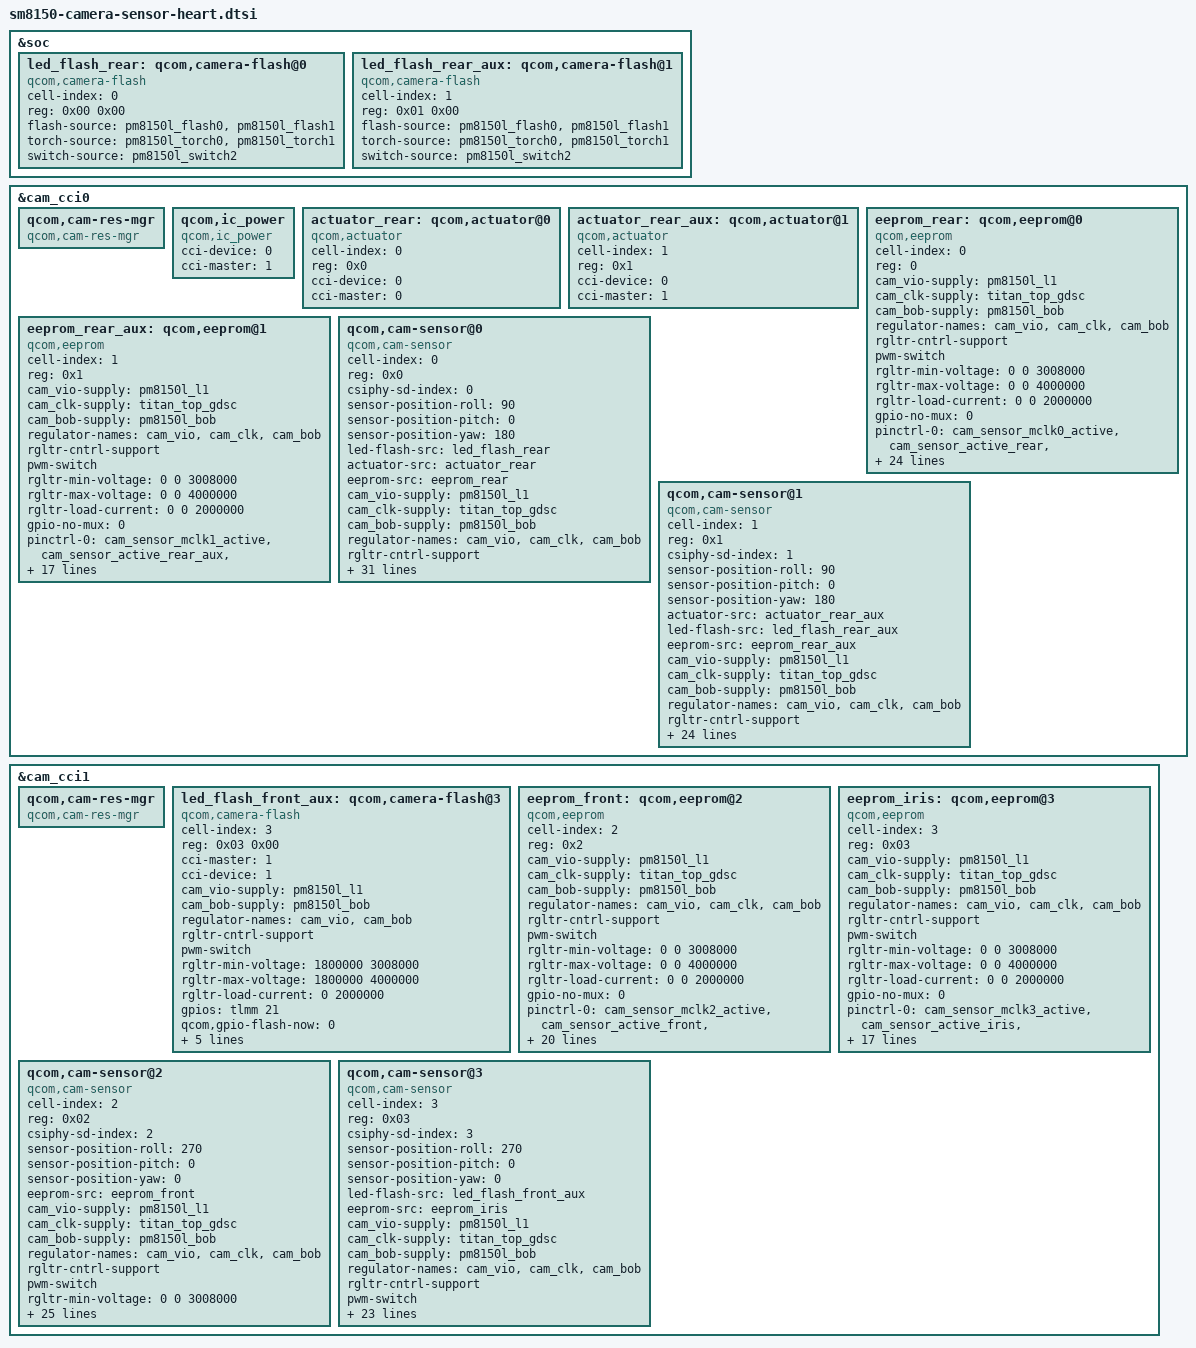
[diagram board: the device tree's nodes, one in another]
/*
 * Copyright (c) 2018, The Linux Foundation. All rights reserved.
 *
 * This program is free software; you can redistribute it and/or modify
 * it under the terms of the GNU General Public License version 2 and
 * only version 2 as published by the Free Software Foundation.
 *
 * This program is distributed in the hope that it will be useful,
 * but WITHOUT ANY WARRANTY; without even the implied warranty of
 * MERCHANTABILITY or FITNESS FOR A PARTICULAR PURPOSE.  See the
 * GNU General Public License for more details.
 */

&soc {
	led_flash_rear: qcom,camera-flash@0 {
		cell-index = <0>;
		reg = <0x00 0x00>;
		compatible = "qcom,camera-flash";
		flash-source = <&pm8150l_flash0 &pm8150l_flash1>;
		torch-source = <&pm8150l_torch0 &pm8150l_torch1>;
		switch-source = <&pm8150l_switch2>;
		status = "ok";
	};

	led_flash_rear_aux: qcom,camera-flash@1 {
		cell-index = <1>;
		reg = <0x01 0x00>;
		compatible = "qcom,camera-flash";
		flash-source = <&pm8150l_flash0 &pm8150l_flash1>;
		torch-source = <&pm8150l_torch0 &pm8150l_torch1>;
		switch-source = <&pm8150l_switch2>;
		status = "ok";
	};
/*
	led_flash_iris: qcom,camera-flash@3 {
		cell-index = <3>;
		reg = <0x03 0x00>;
		compatible = "qcom,camera-flash";
		flash-source = <&pm8150l_flash1>;
		torch-source = <&pm8150l_torch1>;
		switch-source = <&pm8150l_switch0>;
		status = "ok";
	};

	led_flash_i2c: qcom,camera-flash@63 {
		cell-index = <2>;
		reg = <0x02 0x00>;
		compatible = "qcom,camera-flash";
		flash-source = <&pm8150l_flash2>;
		torch-source = <&pm8150l_torch2>;
		switch-source = <&pm8150l_switch1>;
		qcom,slave-id = <0x63 0x00 0x0017>;
		cci-master = <0>;
		gpios = <&tlmm 21 0>;
		qcom,gpio-flash-now = <0>;
		qcom,gpio-req-tbl-num = <0>;
		qcom,gpio-req-tbl-flags = <0>;
		qcom,gpio-req-tbl-label = "FLASH_NOW";
		qcom,max-current = <1000>;
		qcom,max-duration = <1200>;
	};
*/
};

&cam_cci0 {
	qcom,cam-res-mgr {
		compatible = "qcom,cam-res-mgr";
		status = "ok";
	};

	qcom,ic_power {
		compatible = "qcom,ic_power";
		cci-device = <0>;
		cci-master = <1>;
		status = "ok";
	};

	actuator_rear: qcom,actuator@0 {
		cell-index = <0>;
		reg = <0x0>;
		compatible = "qcom,actuator";
		cci-device = <0>;
		cci-master = <0>;
		/*cam_vaf-supply = <&pm8009_s2>;
		regulator-names = "cam_vaf";
		rgltr-cntrl-support;
		rgltr-min-voltage = <2856000>;
		rgltr-max-voltage = <2856000>;
		rgltr-load-current = <0>;*/
	};

	actuator_rear_aux: qcom,actuator@1 {
		cell-index = <1>;
		reg = <0x1>;
		compatible = "qcom,actuator";
		cci-device = <0>;
		cci-master = <1>;
		/*cam_vaf-supply = <&pm8009_s2>;
		regulator-names = "cam_vaf";
		rgltr-cntrl-support;
		rgltr-min-voltage = <2856000>;
		rgltr-max-voltage = <2856000>;
		rgltr-load-current = <0>;*/
	};

	eeprom_rear: qcom,eeprom@0 {
		cell-index = <0>;
		reg = <0>;
		compatible = "qcom,eeprom";
		cam_vio-supply = <&pm8150l_l1>;
		//cam_vaf-supply = <&actuator_regulator>;
		cam_clk-supply = <&titan_top_gdsc>;
		cam_bob-supply = <&pm8150l_bob>;
		regulator-names = "cam_vio", "cam_clk", "cam_bob";
		rgltr-cntrl-support;
		pwm-switch;
		rgltr-min-voltage = <0 0 3008000>;
		rgltr-max-voltage = <0 0 4000000>;
		rgltr-load-current = <0 0 2000000>;
		gpio-no-mux = <0>;
		pinctrl-names = "cam_default", "cam_suspend";
		pinctrl-0 = <&cam_sensor_mclk0_active
				&cam_sensor_active_rear
				&cam_sensor_rear_vana_active
				&cam_sensor_rear_dvdd_en_active
				&cam_sensor_rear_vcm_active>;
		pinctrl-1 = <&cam_sensor_mclk0_suspend
				&cam_sensor_suspend_rear
				&cam_sensor_rear_vana_suspend
				&cam_sensor_rear_dvdd_en_suspend
				&cam_sensor_rear_vcm_suspend>;
		gpios = <&tlmm 13 0>,
			<&tlmm 28 0>,
			<&tlmm 11 0>,
			<&pm8150l_gpios 3 0>,
			<&tlmm 29 0>;
		gpio-reset = <1>;
		gpio-vana = <2>;
		gpio-vdig = <3>;
		gpio-vaf = <4>;
		gpio-req-tbl-num = <0 1 2 3 4>;
		gpio-req-tbl-flags = <1 0 0 0 0>;
		gpio-req-tbl-label = "CAMIF_MCLK0",
					"CAM_RESET0",
					"CAM_VANA0",
					"CAM_DVDD0",
					"CAM_VAF0";
		sensor-mode = <0>;
		cci-device = <0>;
		cci-master = <0>;
		status = "ok";
		clocks = <&clock_camcc CAM_CC_MCLK0_CLK>;
		clock-names = "cam_clk";
		clock-cntl-level = "turbo";
		clock-rates = <24000000>;
	};

	eeprom_rear_aux: qcom,eeprom@1 {
		cell-index = <1>;
		reg = <0x1>;
		compatible = "qcom,eeprom";
		cam_vio-supply = <&pm8150l_l1>;
		cam_clk-supply = <&titan_top_gdsc>;
		cam_bob-supply = <&pm8150l_bob>;
		regulator-names = "cam_vio", "cam_clk", "cam_bob";
		rgltr-cntrl-support;
		pwm-switch;
		rgltr-min-voltage = <0 0 3008000>;
		rgltr-max-voltage = <0 0 4000000>;
		rgltr-load-current = <0 0 2000000>;
		gpio-no-mux = <0>;
		pinctrl-names = "cam_default", "cam_suspend";
		pinctrl-0 = <&cam_sensor_mclk1_active
				&cam_sensor_active_rear_aux
				&cam_sensor_aux_vcm_en_active>;
		pinctrl-1 = <&cam_sensor_mclk1_suspend
				&cam_sensor_suspend_rear_aux
				&cam_sensor_aux_vcm_en_suspend>;
		gpios = <&tlmm 14 0>,
			<&tlmm 30 0>,
			<&tlmm 9 0>;
		gpio-reset = <1>;
		gpio-custom1 = <2>;
		gpio-req-tbl-num = <0 1 2>;
		gpio-req-tbl-flags = <1 0 0>;
		gpio-req-tbl-label = "CAMIF_MCLK1",
					"CAM_RESET1",
					"CAM_CUSTOM1";
		sensor-mode = <0>;
		cci-device = <0>;
		cci-master = <1>;
		status = "ok";
		clocks = <&clock_camcc CAM_CC_MCLK1_CLK>;
		clock-names = "cam_clk";
		clock-cntl-level = "turbo";
		clock-rates = <24000000>;
	};

	qcom,cam-sensor@0 {
		cell-index = <0>;
		compatible = "qcom,cam-sensor";
		reg = <0x0>;
		csiphy-sd-index = <0>;
		sensor-position-roll = <90>;
		sensor-position-pitch = <0>;
		sensor-position-yaw = <180>;
		led-flash-src = <&led_flash_rear>;
		actuator-src = <&actuator_rear>;
		eeprom-src = <&eeprom_rear>;
		cam_vio-supply = <&pm8150l_l1>;
        //cam_vaf-supply = <&actuator_regulator>;
		cam_clk-supply = <&titan_top_gdsc>;
		cam_bob-supply = <&pm8150l_bob>;
		regulator-names = "cam_vio", "cam_clk", "cam_bob";
		rgltr-cntrl-support;
		pwm-switch;
		rgltr-min-voltage = <0 0 3008000>;
		rgltr-max-voltage = <0 0 4000000>;
		rgltr-load-current = <0 0 2000000>;
		gpio-no-mux = <0>;
		pinctrl-names = "cam_default", "cam_suspend";
		pinctrl-0 = <&cam_sensor_mclk0_active
				&cam_sensor_active_rear
				&cam_sensor_rear_vana_active
				&cam_sensor_rear_dvdd_en_active
				&cam_sensor_rear_vcm_active>;
		pinctrl-1 = <&cam_sensor_mclk0_suspend
				&cam_sensor_suspend_rear
				&cam_sensor_rear_vana_suspend
				&cam_sensor_rear_dvdd_en_suspend
				&cam_sensor_rear_vcm_suspend>;
		gpios = <&tlmm 13 0>,
			<&tlmm 28 0>,
			<&tlmm 11 0>,
			<&pm8150l_gpios 3 0>,
			<&tlmm 29 0>;
		gpio-reset = <1>;
		gpio-vana = <2>;
		gpio-vdig = <3>;
		gpio-vaf = <4>;
		gpio-req-tbl-num = <0 1 2 3 4>;
		gpio-req-tbl-flags = <1 0 0 0 0>;
		gpio-req-tbl-label = "CAMIF_MCLK0",
					"CAM_RESET0",
					"CAM_VANA0",
					"CAM_DVDD0",
					"CAM_VAF0";
		sensor-mode = <0>;
		cci-device = <0>;
		cci-master = <0>;
		status = "ok";
		clocks = <&clock_camcc CAM_CC_MCLK0_CLK>;
		clock-names = "cam_clk";
		clock-cntl-level = "turbo";
		clock-rates = <24000000>;
	};

	qcom,cam-sensor@1 {
		cell-index = <1>;
		compatible = "qcom,cam-sensor";
		reg = <0x1>;
		csiphy-sd-index = <1>;
		sensor-position-roll = <90>;
		sensor-position-pitch = <0>;
		sensor-position-yaw = <180>;
		actuator-src = <&actuator_rear_aux>;
		led-flash-src = <&led_flash_rear_aux>;
		eeprom-src = <&eeprom_rear_aux>;
		cam_vio-supply = <&pm8150l_l1>;
		cam_clk-supply = <&titan_top_gdsc>;
		cam_bob-supply = <&pm8150l_bob>;
		regulator-names = "cam_vio", "cam_clk", "cam_bob";
		rgltr-cntrl-support;
		pwm-switch;
		rgltr-min-voltage = <0 0 3008000>;
		rgltr-max-voltage = <0 0 4000000>;
		rgltr-load-current = <0 0 2000000>;
		gpio-no-mux = <0>;
		pinctrl-names = "cam_default", "cam_suspend";
		pinctrl-0 = <&cam_sensor_mclk1_active
				&cam_sensor_active_rear_aux
				&cam_sensor_aux_vcm_en_active>;
		pinctrl-1 = <&cam_sensor_mclk1_suspend
				&cam_sensor_suspend_rear_aux
				&cam_sensor_aux_vcm_en_suspend>;
		gpios = <&tlmm 14 0>,
			<&tlmm 30 0>,
			<&tlmm 9 0>;
		gpio-reset = <1>;
		gpio-custom1 = <2>;
		gpio-req-tbl-num = <0 1 2>;
		gpio-req-tbl-flags = <1 0 0>;
		gpio-req-tbl-label = "CAMIF_MCLK1",
					"CAM_RESET1",
					"CAM_CUSTOM1";
		sensor-mode = <0>;
		cci-device = <0>;
		cci-master = <1>;
		status = "ok";
		clocks = <&clock_camcc CAM_CC_MCLK1_CLK>;
		clock-names = "cam_clk";
		clock-cntl-level = "turbo";
		clock-rates = <24000000>;
	};
};

&cam_cci1 {
	qcom,cam-res-mgr {
		compatible = "qcom,cam-res-mgr";
		status = "ok";
	};

	led_flash_front_aux: qcom,camera-flash@3 {
		cell-index = <3>;
		reg = <0x03 0x00>;
		compatible = "qcom,camera-flash";
		cci-master = <1>;
		cci-device = <1>;
		cam_vio-supply = <&pm8150l_l1>;
		cam_bob-supply = <&pm8150l_bob>;
		regulator-names = "cam_vio", "cam_bob";
		rgltr-cntrl-support;
		pwm-switch;
		rgltr-min-voltage = <1800000 3008000>;
		rgltr-max-voltage = <1800000 4000000>;
		rgltr-load-current = <0 2000000>;
		gpios = <&tlmm 21 0>;
		qcom,gpio-flash-now = <0>;
		qcom,gpio-req-tbl-num = <0>;
		qcom,gpio-req-tbl-flags = <0>;
		qcom,gpio-req-tbl-label = "FLASH_NOW";
		qcom,max-current = <1000>;
		qcom,max-duration = <1200>;
		status = "ok";
	};

	eeprom_front: qcom,eeprom@2 {
		cell-index = <2>;
		reg = <0x2>;
		compatible = "qcom,eeprom";
		cam_vio-supply = <&pm8150l_l1>;
		cam_clk-supply = <&titan_top_gdsc>;
		cam_bob-supply = <&pm8150l_bob>;
		regulator-names = "cam_vio", "cam_clk", "cam_bob";
		rgltr-cntrl-support;
		pwm-switch;
		rgltr-min-voltage = <0 0 3008000>;
		rgltr-max-voltage = <0 0 4000000>;
		rgltr-load-current = <0 0 2000000>;
		gpio-no-mux = <0>;
		pinctrl-names = "cam_default", "cam_suspend";
		pinctrl-0 = <&cam_sensor_mclk2_active
				 &cam_sensor_active_front
				 &cam_sensor_front_vana_active
				 &cam_sensor_front_dvdd_active>;
		pinctrl-1 = <&cam_sensor_mclk2_suspend
				 &cam_sensor_suspend_front
				 &cam_sensor_front_vana_suspend
				 &cam_sensor_front_dvdd_suspend>;
		gpios = <&tlmm 15 0>,
			<&tlmm 12 0>,
			<&tlmm 25 0>,
			<&tlmm 26 0>;
		gpio-reset = <1>;
		gpio-vana = <2>;
		gpio-vdig = <3>;
		gpio-req-tbl-num = <0 1 2 3>;
		gpio-req-tbl-flags = <1 0 0 0>;
		gpio-req-tbl-label = "CAMIF_MCLK2",
					"CAM_RESET2",
					"CAM_VANA2",
					"CAM_DVDD2";
		sensor-mode = <0>;
		cci-device = <1>;
		cci-master = <0>;
		status = "ok";
		clocks = <&clock_camcc CAM_CC_MCLK2_CLK>;
		clock-names = "cam_clk";
		clock-cntl-level = "turbo";
		clock-rates = <24000000>;
	};

	eeprom_iris: qcom,eeprom@3 {
		cell-index = <3>;
		compatible = "qcom,eeprom";
		reg = <0x03>;
		cam_vio-supply = <&pm8150l_l1>;
		cam_clk-supply = <&titan_top_gdsc>;
		cam_bob-supply = <&pm8150l_bob>;
		regulator-names = "cam_vio","cam_clk", "cam_bob";
		rgltr-cntrl-support;
		pwm-switch;
		rgltr-min-voltage = <0 0 3008000>;
		rgltr-max-voltage = <0 0 4000000>;
		rgltr-load-current = <0 0 2000000>;
		gpio-no-mux = <0>;
		pinctrl-names = "cam_default", "cam_suspend";
		pinctrl-0 = <&cam_sensor_mclk3_active
		                 &cam_sensor_active_iris
		                 &cam_sensor_aux_vcm_en_active>;
		pinctrl-1 = <&cam_sensor_mclk3_suspend
		                 &cam_sensor_active_iris
		                 &cam_sensor_aux_vcm_en_suspend>;
		gpios = <&tlmm 16 0>,
		        <&tlmm 23 0>,
		        <&tlmm 9 0>;
		gpio-reset = <1>;
		gpio-custom2 = <2>;
		gpio-req-tbl-num = <0 1 2>;
		gpio-req-tbl-flags = <1 0 0>;
		gpio-req-tbl-label = "CAMIF_MCLK3",
		                        "CAM_RESET3",
		                        "CAM_CUSTOM2";
		sensor-mode = <0>;
		cci-device = <1>;
		cci-master = <1>;
		status = "ok";
		clocks = <&clock_camcc CAM_CC_MCLK3_CLK>;
		clock-names = "cam_clk";
		clock-cntl-level = "turbo";
		clock-rates = <24000000>;
	};

	qcom,cam-sensor@2 {
		cell-index = <2>;
		compatible = "qcom,cam-sensor";
		reg = <0x02>;
		csiphy-sd-index = <2>;
		sensor-position-roll = <270>;
		sensor-position-pitch = <0>;
		sensor-position-yaw = <0>;
		eeprom-src = <&eeprom_front>;
		cam_vio-supply = <&pm8150l_l1>;
		cam_clk-supply = <&titan_top_gdsc>;
		cam_bob-supply = <&pm8150l_bob>;
		regulator-names = "cam_vio", "cam_clk", "cam_bob";
		rgltr-cntrl-support;
		pwm-switch;
		rgltr-min-voltage = <0 0 3008000>;
		rgltr-max-voltage = <0 0 4000000>;
		rgltr-load-current = <0 0 2000000>;
		gpio-no-mux = <0>;
		pinctrl-names = "cam_default", "cam_suspend";
		pinctrl-0 = <&cam_sensor_mclk2_active
				 &cam_sensor_active_front
				 &cam_sensor_front_vana_active
				 &cam_sensor_front_dvdd_active>;
		pinctrl-1 = <&cam_sensor_mclk2_suspend
				 &cam_sensor_suspend_front
				 &cam_sensor_front_vana_suspend
				 &cam_sensor_front_dvdd_suspend>;
		gpios = <&tlmm 15 0>,
			<&tlmm 12 0>,
			<&tlmm 25 0>,
			<&tlmm 26 0>;
		gpio-reset = <1>;
		gpio-vana = <2>;
		gpio-vdig = <3>;
		gpio-req-tbl-num = <0 1 2 3>;
		gpio-req-tbl-flags = <1 0 0 0>;
		gpio-req-tbl-label = "CAMIF_MCLK2",
					"CAM_RESET2",
					"CAM_VANA2",
					"CAM_DVDD2";
		sensor-mode = <0>;
		cci-device = <1>;
		cci-master = <0>;
		status = "ok";
		clocks = <&clock_camcc CAM_CC_MCLK2_CLK>;
		clock-names = "cam_clk";
		clock-cntl-level = "turbo";
		clock-rates = <24000000>;
	};

	qcom,cam-sensor@3 {
		cell-index = <3>;
		compatible = "qcom,cam-sensor";
		reg = <0x03>;
		csiphy-sd-index = <3>;
		sensor-position-roll = <270>;
		sensor-position-pitch = <0>;
		sensor-position-yaw = <0>;
		led-flash-src = <&led_flash_front_aux>;
		eeprom-src = <&eeprom_iris>;
		cam_vio-supply = <&pm8150l_l1>;
		cam_clk-supply = <&titan_top_gdsc>;
		cam_bob-supply = <&pm8150l_bob>;
		regulator-names = "cam_vio","cam_clk", "cam_bob";
		rgltr-cntrl-support;
		pwm-switch;
		rgltr-min-voltage = <0 0 3008000>;
		rgltr-max-voltage = <0 0 4000000>;
		rgltr-load-current = <0 0 2000000>;
		gpio-no-mux = <0>;
		pinctrl-names = "cam_default", "cam_suspend";
		pinctrl-0 = <&cam_sensor_mclk3_active
				 &cam_sensor_active_iris
				 &cam_sensor_aux_vcm_en_active>;
		pinctrl-1 = <&cam_sensor_mclk3_suspend
				 &cam_sensor_active_iris
				 &cam_sensor_aux_vcm_en_suspend>;
		gpios = <&tlmm 16 0>,
			<&tlmm 23 0>,
			<&tlmm 9 0>;
		gpio-reset = <1>;
		gpio-custom2 = <2>;
		gpio-req-tbl-num = <0 1 2>;
		gpio-req-tbl-flags = <1 0 0>;
		gpio-req-tbl-label = "CAMIF_MCLK3",
					"CAM_RESET3",
					"CAM_CUSTOM2";
		sensor-mode = <0>;
		cci-device = <1>;
		cci-master = <1>;
		status = "ok";
		clocks = <&clock_camcc CAM_CC_MCLK3_CLK>;
		clock-names = "cam_clk";
		clock-cntl-level = "turbo";
		clock-rates = <24000000>;
	};
};

